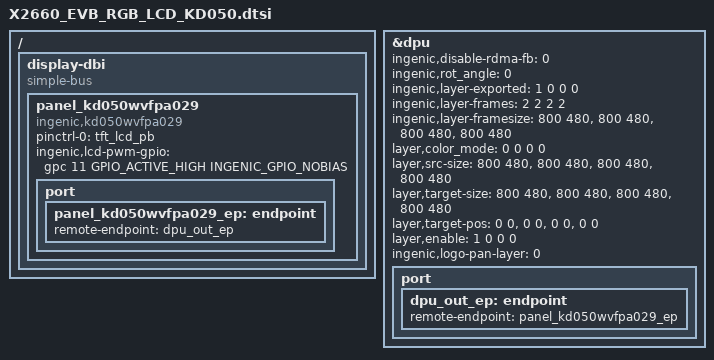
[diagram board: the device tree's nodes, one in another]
&dpu {
	status = "okay";
	ingenic,disable-rdma-fb = <0>;
	ingenic,rot_angle = <0>;
	//Defines the init state of composer fb export infomations.
	ingenic,layer-exported = <1 0 0 0>;
	ingenic,layer-frames   = <2 2 2 2>;
	ingenic,layer-framesize = <800 480>, <800 480>, <800 480>, <800 480>;   //Max framesize for each layer.
	layer,color_mode        = <0 0 0 0>;                                    //src fmt,
	layer,src-size          = <800 480>, <800 480>, <800 480>, <800 480>; //Layer src size should smaller than framesize
        layer,target-size       = <800 480>, <800 480>, <800 480>, <800 480>;  //Target Size should smaller than src_size.
	layer,target-pos        = <0 0>, <0 0>, <0 0>, <0 0>; //target pos , the start point of the target panel.
	layer,enable            = <1 0 0 0>;                                    //layer enabled or disabled.
	ingenic,logo-pan-layer  = <0>;                                          //on which layer should init logo pan on.
	port {
		dpu_out_ep: endpoint {
		    remote-endpoint = <&panel_kd050wvfpa029_ep>;
	    };
	};
};
/*RGB*/
/ {
	display-dbi {
		compatible = "simple-bus";
		#interrupt-cells = <1>;
		#address-cells = <1>;
		#size-cells = <1>;
		ranges = <>;
		panel_kd050wvfpa029 {
			compatible = "ingenic,kd050wvfpa029";
			status = "okay";
			pinctrl-names = "default";
			pinctrl-0 = <&tft_lcd_pb>;
			ingenic,lcd-pwm-gpio = <&gpc 11 GPIO_ACTIVE_HIGH INGENIC_GPIO_NOBIAS>;
			port {
				panel_kd050wvfpa029_ep: endpoint {
					remote-endpoint = <&dpu_out_ep>;
				};
			};
		};
	};
};

